# RS1xxxx register map
Vendor: Silicon Lab Inc.; Series: ARMCM4; File version: 1.2
CPU: CM4 r1p0, little endian, MPU, FPU, 6 interrupt priority bits
Registers are 32-bit, read-write, reset 0x0 unless marked. A register's access mark holds for its fields unless they carry their own. Offsets are from the block's base; [hi:lo] are bit positions.

## EFUSE_Controller — The EFUSE controller is used to provide an interface to one time program memory (EFUSE macro) to perform write and read operations
Base 0x4600C000
0x00 EFUSE_DA_ADDR_REG — Direct Access Registers
  [15:0] ADDR_BITS — These bits specifies the address to write or read from EFUSE macro model
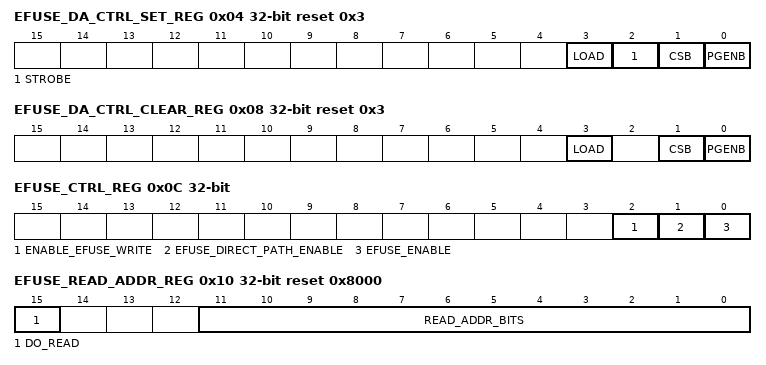
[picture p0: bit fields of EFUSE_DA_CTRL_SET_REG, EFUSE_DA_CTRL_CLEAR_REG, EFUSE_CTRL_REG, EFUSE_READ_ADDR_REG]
0x04 EFUSE_DA_CTRL_SET_REG reset 0x3 — Direct Access Set Registers
  [3] LOAD — Set Load enable
    1=enable (Sets EFUSE load enable (LOAD) pin when direct accessing is enabled); 0=disable (no effect)
  [2] STROBE — Set strobe enable
    1=enable (Sets EFUSE STROBE enable (STROBE) pin when direct accessing is enabled); 0=disable (no effect)
  [1] CSB — Set Chip Enable
    1=enable (Sets EFUSE Chip enable (CSB) pin when direct accessing is enabled); 0=disable (no effect)
  [0] PGENB — Set Program enable
    1=enable (Sets EFUSE program enable (PGENB) pin when direct accessing is enabled); 0=disable (no effect)
0x08 EFUSE_DA_CTRL_CLEAR_REG reset 0x3 — Direct Access Clear Registers
  [3] LOAD — Clear Load enable
    1=enable (Clear EFUSE load enable (LOAD) pin when direct accessing is enabled); 0=disable (no effect)
  [1] CSB — Clear Chip Enable
    1=enable (Clear EFUSE Chip enable (CSB) pin when direct accessing is enabled); 0=disable (no effect)
  [0] PGENB — Clear Program enable
    1=enable (Clear EFUSE program enable (PGENB) pin when direct accessing is enabled); 0=disable (no effect)
0x0C EFUSE_CTRL_REG — Control Register
  [2] ENABLE_EFUSE_WRITE — Controls the switch on VDDIQ for eFuse read/write.
    1=enable (VDDIQ is supplied); 0=disable (VDDIQ is gated)
  [1] EFUSE_DIRECT_PATH_ENABLE — This bit specifies whether the EFUSE direct path is enabled or not for direct accessing of the EFUSE pins
    1=enable (EFUSE direct accessing enabled); 0=disable (EFUSE direct accessing disabled)
  [0] EFUSE_ENABLE — This bit specifies whether the EFUSE module is enabled or not
    1=enable (EFUSE module enabled); 0=disable (EFUSE module disabled)
0x10 EFUSE_READ_ADDR_REG reset 0x8000 — Read address Register
  [15] DO_READ wo — Enables read FSM after EFUSE is enabled
  [11:0] READ_ADDR_BITS — These bits specifies the address from which read operation has to be performed
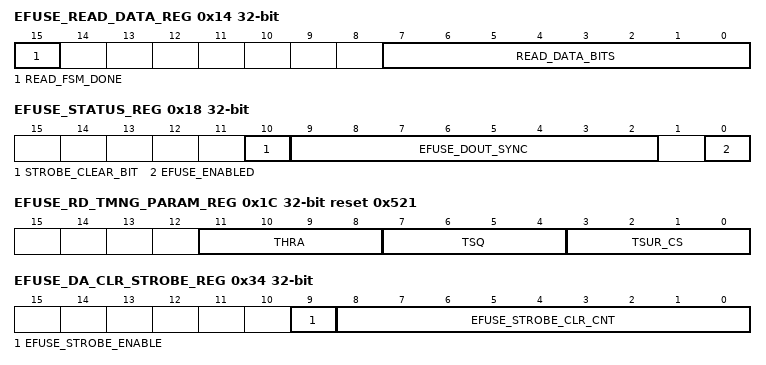
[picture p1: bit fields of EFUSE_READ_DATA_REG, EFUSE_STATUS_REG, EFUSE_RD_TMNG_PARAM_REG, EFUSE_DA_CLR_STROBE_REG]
0x14 EFUSE_READ_DATA_REG — Read address Register
  [15] READ_FSM_DONE ro — Indicates read fsm is done. After this read data is available in EFUSE_READ_DATA_REGISTER bits [7:0]
  [7:0] READ_DATA_BITS — These bits specifies the data bits that are read from a given address specified in the EFUSE_READ_ADDRESS_REGISTER bits [8:0]
0x18 EFUSE_STATUS_REG ro — Read address Register
  [10] STROBE_CLEAR_BIT — This bit indicates STROBE signal goes low after strobe count value reached '0'
  [9:2] EFUSE_DOUT_SYNC — This bit specifies the 8-bit data read out from the EFUSE macro. This is synchronized with pclk
  [0] EFUSE_ENABLED — This bit specifies whether the EFUSE is enabled or not
0x1C EFUSE_RD_TMNG_PARAM_REG reset 0x521
  [11:8] THRA — for 32x8 macro: A4 A0 to STROBE hold time into Read mode 5122x8 macro: A8 A0 to STROBE hold time into Read mode
  [7:4] TSQ — Q7-Q0 access time from STROBE rising edge
  [3:0] TSUR_CS — CSB to STROBE setup time into read mode
0x24 EFUSE_MEM_MAP_LENGTH_REG
  [0] EFUSE_MEM_MAP_LEN — 0: 8 bit read 1: 16 bit read
0x28 EFUSE_READ_BLOCK_STARTING_LOCATION — Starting address from which the read has to be blocked. Once the end address is written, it cannot be changed till power on reset is given
  [15:0] EFUSE_READ_BLOCK_STARTING_LOCATION — Starting address from which the read has to be blocked. Once the end address is written, it cannot be changed till power on reset is given.
0x2C EFUSE_READ_BLOCK_END_LOCATION — Starting address from which the read has to be blocked. Once the end address is written, it cannot be changed till power on reset is given
  [15:0] EFUSE_READ_BLOCK_END_LOCATION — End address till which the read has to be blocked. Once the end address is written , it cannot be changed till power on reset is given.
0x30 EFUSE_READ_BLOCK_ENABLE_REG — The Transmit Poll Demand register enables the Transmit DMA to check whether or not the current descriptor is owned by DMA
  [0] EFUSE_READ_BLOCK_ENABLE — Enable for blocking the read access from a programmable memory location
0x34 EFUSE_DA_CLR_STROBE_REG
  [9] EFUSE_STROBE_ENABLE
  [8:0] EFUSE_STROBE_CLR_CNT — Strobe signal Clear count in direct access mode. value depends on APB clock frequency of eFuse controller
